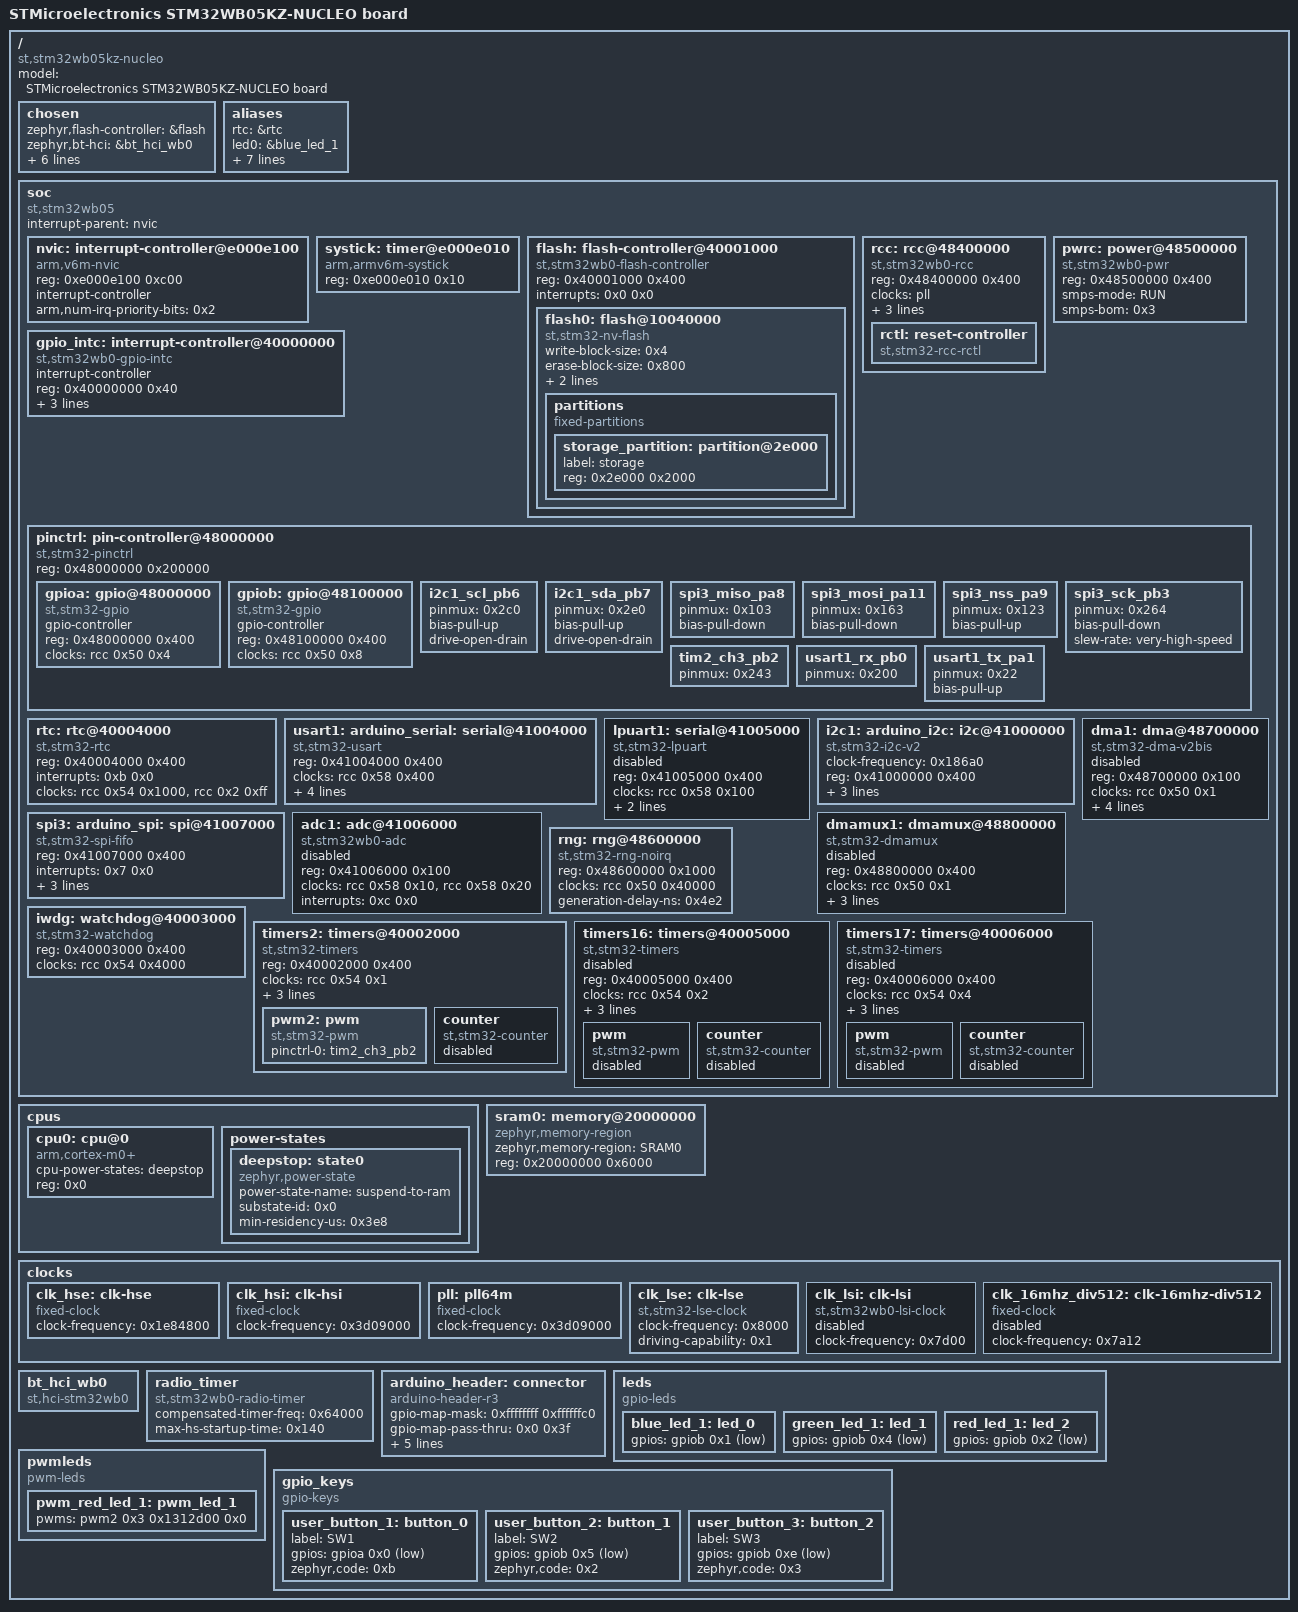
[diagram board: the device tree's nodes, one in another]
/dts-v1/;

/* node '/' defined in zephyr/dts/common/skeleton.dtsi:9 */
/ {
	model = "STMicroelectronics STM32WB05KZ-NUCLEO board"; /* in zephyr/boards/st/nucleo_wb05kz/nucleo_wb05kz.dts:15 */
	compatible = "st,stm32wb05kz-nucleo";                  /* in zephyr/boards/st/nucleo_wb05kz/nucleo_wb05kz.dts:16 */
	#address-cells = < 0x1 >;                              /* in zephyr/boards/st/nucleo_wb05kz/nucleo_wb05kz.dts:18 */
	#size-cells = < 0x1 >;                                 /* in zephyr/boards/st/nucleo_wb05kz/nucleo_wb05kz.dts:19 */

	/* node '/chosen' defined in zephyr/dts/common/skeleton.dtsi:13 */
	chosen {
		zephyr,flash-controller = &flash; /* in zephyr/dts/arm/st/wb0/stm32wb0.dtsi:25 */
		zephyr,bt-hci = &bt_hci_wb0;      /* in zephyr/dts/arm/st/wb0/stm32wb0.dtsi:26 */
		zephyr,console = &usart1;         /* in zephyr/boards/st/nucleo_wb05kz/nucleo_wb05kz.dts:22 */
		zephyr,shell-uart = &usart1;      /* in zephyr/boards/st/nucleo_wb05kz/nucleo_wb05kz.dts:23 */
		zephyr,sram = &sram0;             /* in zephyr/boards/st/nucleo_wb05kz/nucleo_wb05kz.dts:24 */
		zephyr,flash = &flash0;           /* in zephyr/boards/st/nucleo_wb05kz/nucleo_wb05kz.dts:25 */
		zephyr,bt-c2h-uart = &usart1;     /* in zephyr/boards/st/nucleo_wb05kz/nucleo_wb05kz.dts:26 */
		zephyr,entropy = &rng;            /* in zephyr/boards/st/nucleo_wb05kz/nucleo_wb05kz.dts:27 */
	};

	/* node '/aliases' defined in zephyr/dts/common/skeleton.dtsi:15 */
	aliases {
		rtc = &rtc;                /* in zephyr/boards/st/nucleo_wb05kz/nucleo_wb05kz.dts:78 */
		led0 = &blue_led_1;        /* in zephyr/boards/st/nucleo_wb05kz/nucleo_wb05kz.dts:79 */
		led1 = &green_led_1;       /* in zephyr/boards/st/nucleo_wb05kz/nucleo_wb05kz.dts:80 */
		led2 = &red_led_1;         /* in zephyr/boards/st/nucleo_wb05kz/nucleo_wb05kz.dts:81 */
		pwm-led0 = &pwm_red_led_1; /* in zephyr/boards/st/nucleo_wb05kz/nucleo_wb05kz.dts:82 */
		sw0 = &user_button_1;      /* in zephyr/boards/st/nucleo_wb05kz/nucleo_wb05kz.dts:83 */
		sw1 = &user_button_2;      /* in zephyr/boards/st/nucleo_wb05kz/nucleo_wb05kz.dts:84 */
		sw2 = &user_button_3;      /* in zephyr/boards/st/nucleo_wb05kz/nucleo_wb05kz.dts:85 */
		watchdog0 = &iwdg;         /* in zephyr/boards/st/nucleo_wb05kz/nucleo_wb05kz.dts:86 */
	};

	/* node '/soc' defined in zephyr/dts/arm/armv6-m.dtsi:6 */
	soc {
		#address-cells = < 0x1 >;     /* in zephyr/dts/arm/armv6-m.dtsi:7 */
		#size-cells = < 0x1 >;        /* in zephyr/dts/arm/armv6-m.dtsi:8 */
		interrupt-parent = < &nvic >; /* in zephyr/dts/arm/armv6-m.dtsi:10 */
		ranges;                       /* in zephyr/dts/arm/armv6-m.dtsi:11 */
		compatible = "st,stm32wb05",
		             "st,stm32wb0",
		             "simple-bus";    /* in zephyr/dts/arm/st/wb0/stm32wb05.dtsi:11 */

		/* node '/soc/interrupt-controller@e000e100' defined in zephyr/dts/arm/armv6-m.dtsi:13 */
		nvic: interrupt-controller@e000e100 {
			#address-cells = < 0x1 >;            /* in zephyr/dts/arm/armv6-m.dtsi:14 */
			compatible = "arm,v6m-nvic";         /* in zephyr/dts/arm/armv6-m.dtsi:15 */
			reg = < 0xe000e100 0xc00 >;          /* in zephyr/dts/arm/armv6-m.dtsi:16 */
			interrupt-controller;                /* in zephyr/dts/arm/armv6-m.dtsi:17 */
			#interrupt-cells = < 0x2 >;          /* in zephyr/dts/arm/armv6-m.dtsi:18 */
			arm,num-irq-priority-bits = < 0x2 >; /* in zephyr/dts/arm/st/wb0/stm32wb0.dtsi:326 */
			phandle = < 0x1 >;                   /* in zephyr/dts/arm/armv6-m.dtsi:10 */
		};

		/* node '/soc/timer@e000e010' defined in zephyr/dts/arm/armv6-m.dtsi:21 */
		systick: timer@e000e010 {
			compatible = "arm,armv6m-systick"; /* in zephyr/dts/arm/armv6-m.dtsi:22 */
			reg = < 0xe000e010 0x10 >;         /* in zephyr/dts/arm/armv6-m.dtsi:23 */
		};

		/* node '/soc/flash-controller@40001000' defined in zephyr/dts/arm/st/wb0/stm32wb0.dtsi:125 */
		flash: flash-controller@40001000 {
			compatible = "st,stm32wb0-flash-controller",
			             "st,stm32-flash-controller";    /* in zephyr/dts/arm/st/wb0/stm32wb0.dtsi:126 */
			reg = < 0x40001000 0x400 >;                  /* in zephyr/dts/arm/st/wb0/stm32wb0.dtsi:127 */
			interrupts = < 0x0 0x0 >;                    /* in zephyr/dts/arm/st/wb0/stm32wb0.dtsi:128 */
			#address-cells = < 0x1 >;                    /* in zephyr/dts/arm/st/wb0/stm32wb0.dtsi:130 */
			#size-cells = < 0x1 >;                       /* in zephyr/dts/arm/st/wb0/stm32wb0.dtsi:131 */

			/* node '/soc/flash-controller@40001000/flash@10040000' defined in zephyr/dts/arm/st/wb0/stm32wb0.dtsi:133 */
			flash0: flash@10040000 {
				compatible = "st,stm32-nv-flash",
				             "soc-nv-flash";      /* in zephyr/dts/arm/st/wb0/stm32wb0.dtsi:134 */
				write-block-size = < 0x4 >;       /* in zephyr/dts/arm/st/wb0/stm32wb0.dtsi:135 */
				erase-block-size = < 0x800 >;     /* in zephyr/dts/arm/st/wb0/stm32wb0.dtsi:136 */
				max-erase-time = < 0x28 >;        /* in zephyr/dts/arm/st/wb0/stm32wb0.dtsi:138 */
				reg = < 0x10040000 0x30000 >;     /* in zephyr/dts/arm/st/wb0/stm32wb05Xz.dtsi:13 */

				/* node '/soc/flash-controller@40001000/flash@10040000/partitions' defined in zephyr/boards/st/nucleo_wb05kz/nucleo_wb05kz.dts:179 */
				partitions {
					compatible = "fixed-partitions"; /* in zephyr/boards/st/nucleo_wb05kz/nucleo_wb05kz.dts:180 */
					#address-cells = < 0x1 >;        /* in zephyr/boards/st/nucleo_wb05kz/nucleo_wb05kz.dts:181 */
					#size-cells = < 0x1 >;           /* in zephyr/boards/st/nucleo_wb05kz/nucleo_wb05kz.dts:182 */

					/* node '/soc/flash-controller@40001000/flash@10040000/partitions/partition@2e000' defined in zephyr/boards/st/nucleo_wb05kz/nucleo_wb05kz.dts:185 */
					storage_partition: partition@2e000 {
						label = "storage";        /* in zephyr/boards/st/nucleo_wb05kz/nucleo_wb05kz.dts:186 */
						reg = < 0x2e000 0x2000 >; /* in zephyr/boards/st/nucleo_wb05kz/nucleo_wb05kz.dts:187 */
					};
				};
			};
		};

		/* node '/soc/rcc@48400000' defined in zephyr/dts/arm/st/wb0/stm32wb0.dtsi:142 */
		rcc: rcc@48400000 {
			compatible = "st,stm32wb0-rcc";  /* in zephyr/dts/arm/st/wb0/stm32wb0.dtsi:143 */
			reg = < 0x48400000 0x400 >;      /* in zephyr/dts/arm/st/wb0/stm32wb0.dtsi:144 */
			#clock-cells = < 0x2 >;          /* in zephyr/dts/arm/st/wb0/stm32wb0.dtsi:145 */
			clocks = < &pll >;               /* in zephyr/boards/st/nucleo_wb05kz/nucleo_wb05kz.dts:112 */
			clock-frequency = < 0x3d09000 >; /* in zephyr/boards/st/nucleo_wb05kz/nucleo_wb05kz.dts:113 */
			clksys-prescaler = < 0x1 >;      /* in zephyr/boards/st/nucleo_wb05kz/nucleo_wb05kz.dts:114 */
			slow-clock = < &clk_lse >;       /* in zephyr/boards/st/nucleo_wb05kz/nucleo_wb05kz.dts:115 */
			phandle = < 0x4 >;               /* in zephyr/dts/arm/st/wb0/stm32wb0.dtsi:186 */

			/* node '/soc/rcc@48400000/reset-controller' defined in zephyr/dts/arm/st/wb0/stm32wb0.dtsi:147 */
			rctl: reset-controller {
				compatible = "st,stm32-rcc-rctl"; /* in zephyr/dts/arm/st/wb0/stm32wb0.dtsi:148 */
				#reset-cells = < 0x1 >;           /* in zephyr/dts/arm/st/wb0/stm32wb0.dtsi:149 */
				phandle = < 0x5 >;                /* in zephyr/dts/arm/st/wb0/stm32wb0.dtsi:211 */
			};
		};

		/* node '/soc/power@48500000' defined in zephyr/dts/arm/st/wb0/stm32wb0.dtsi:153 */
		pwrc: power@48500000 {
			compatible = "st,stm32wb0-pwr"; /* in zephyr/dts/arm/st/wb0/stm32wb0.dtsi:154 */
			reg = < 0x48500000 0x400 >;     /* in zephyr/dts/arm/st/wb0/stm32wb0.dtsi:155 */
			smps-mode = "RUN";              /* in zephyr/boards/st/nucleo_wb05kz/nucleo_wb05kz.dts:91 */
			smps-bom = < 0x3 >;             /* in zephyr/boards/st/nucleo_wb05kz/nucleo_wb05kz.dts:92 */
		};

		/* node '/soc/interrupt-controller@40000000' defined in zephyr/dts/arm/st/wb0/stm32wb0.dtsi:163 */
		gpio_intc: interrupt-controller@40000000 {
			compatible = "st,stm32wb0-gpio-intc"; /* in zephyr/dts/arm/st/wb0/stm32wb0.dtsi:164 */
			interrupt-controller;                 /* in zephyr/dts/arm/st/wb0/stm32wb0.dtsi:165 */
			#interrupt-cells = < 0x1 >;           /* in zephyr/dts/arm/st/wb0/stm32wb0.dtsi:166 */
			#address-cells = < 0x1 >;             /* in zephyr/dts/arm/st/wb0/stm32wb0.dtsi:167 */
			reg = < 0x40000000 0x40 >;            /* in zephyr/dts/arm/st/wb0/stm32wb0.dtsi:168 */
			num-lines = < 0x20 >;                 /* in zephyr/dts/arm/st/wb0/stm32wb0.dtsi:169 */
			interrupts = < 0xf 0x0 >,
			             < 0x10 0x0 >;            /* in zephyr/dts/arm/st/wb0/stm32wb0.dtsi:170 */
			interrupt-names = "gpioa",
			                  "gpiob";            /* in zephyr/dts/arm/st/wb0/stm32wb0.dtsi:171 */
			line-ranges = < 0x0 0x10 >,
			              < 0x10 0x10 >;          /* in zephyr/dts/arm/st/wb0/stm32wb0.dtsi:172 */
		};

		/* node '/soc/pin-controller@48000000' defined in zephyr/dts/arm/st/wb0/stm32wb0.dtsi:175 */
		pinctrl: pin-controller@48000000 {
			compatible = "st,stm32-pinctrl"; /* in zephyr/dts/arm/st/wb0/stm32wb0.dtsi:176 */
			#address-cells = < 0x1 >;        /* in zephyr/dts/arm/st/wb0/stm32wb0.dtsi:177 */
			#size-cells = < 0x1 >;           /* in zephyr/dts/arm/st/wb0/stm32wb0.dtsi:178 */
			reg = < 0x48000000 0x200000 >;   /* in zephyr/dts/arm/st/wb0/stm32wb0.dtsi:179 */

			/* node '/soc/pin-controller@48000000/gpio@48000000' defined in zephyr/dts/arm/st/wb0/stm32wb0.dtsi:181 */
			gpioa: gpio@48000000 {
				compatible = "st,stm32-gpio"; /* in zephyr/dts/arm/st/wb0/stm32wb0.dtsi:182 */
				gpio-controller;              /* in zephyr/dts/arm/st/wb0/stm32wb0.dtsi:183 */
				#gpio-cells = < 0x2 >;        /* in zephyr/dts/arm/st/wb0/stm32wb0.dtsi:184 */
				reg = < 0x48000000 0x400 >;   /* in zephyr/dts/arm/st/wb0/stm32wb0.dtsi:185 */
				clocks = < &rcc 0x50 0x4 >;   /* in zephyr/dts/arm/st/wb0/stm32wb0.dtsi:186 */
				phandle = < 0x11 >;           /* in zephyr/boards/st/nucleo_wb05kz/arduino_r3_connector.dtsi:20 */
			};

			/* node '/soc/pin-controller@48000000/gpio@48100000' defined in zephyr/dts/arm/st/wb0/stm32wb0.dtsi:189 */
			gpiob: gpio@48100000 {
				compatible = "st,stm32-gpio"; /* in zephyr/dts/arm/st/wb0/stm32wb0.dtsi:190 */
				gpio-controller;              /* in zephyr/dts/arm/st/wb0/stm32wb0.dtsi:191 */
				#gpio-cells = < 0x2 >;        /* in zephyr/dts/arm/st/wb0/stm32wb0.dtsi:192 */
				reg = < 0x48100000 0x400 >;   /* in zephyr/dts/arm/st/wb0/stm32wb0.dtsi:193 */
				clocks = < &rcc 0x50 0x8 >;   /* in zephyr/dts/arm/st/wb0/stm32wb0.dtsi:194 */
				phandle = < 0x10 >;           /* in zephyr/boards/st/nucleo_wb05kz/arduino_r3_connector.dtsi:20 */
			};

			/* node '/soc/pin-controller@48000000/i2c1_scl_pb6' defined in modules/hal/stm32/dts/st/wb0/stm32wb05kzvx-pinctrl.dtsi:137 */
			i2c1_scl_pb6: i2c1_scl_pb6 {
				pinmux = < 0x2c0 >; /* in modules/hal/stm32/dts/st/wb0/stm32wb05kzvx-pinctrl.dtsi:138 */
				bias-pull-up;       /* in modules/hal/stm32/dts/st/wb0/stm32wb05kzvx-pinctrl.dtsi:139 */
				drive-open-drain;   /* in modules/hal/stm32/dts/st/wb0/stm32wb05kzvx-pinctrl.dtsi:140 */
				phandle = < 0x8 >;  /* in zephyr/boards/st/nucleo_wb05kz/nucleo_wb05kz.dts:148 */
			};

			/* node '/soc/pin-controller@48000000/i2c1_sda_pb7' defined in modules/hal/stm32/dts/st/wb0/stm32wb05kzvx-pinctrl.dtsi:151 */
			i2c1_sda_pb7: i2c1_sda_pb7 {
				pinmux = < 0x2e0 >; /* in modules/hal/stm32/dts/st/wb0/stm32wb05kzvx-pinctrl.dtsi:152 */
				bias-pull-up;       /* in modules/hal/stm32/dts/st/wb0/stm32wb05kzvx-pinctrl.dtsi:153 */
				drive-open-drain;   /* in modules/hal/stm32/dts/st/wb0/stm32wb05kzvx-pinctrl.dtsi:154 */
				phandle = < 0x9 >;  /* in zephyr/boards/st/nucleo_wb05kz/nucleo_wb05kz.dts:148 */
			};

			/* node '/soc/pin-controller@48000000/spi3_miso_pa8' defined in modules/hal/stm32/dts/st/wb0/stm32wb05kzvx-pinctrl.dtsi:211 */
			spi3_miso_pa8: spi3_miso_pa8 {
				pinmux = < 0x103 >; /* in modules/hal/stm32/dts/st/wb0/stm32wb05kzvx-pinctrl.dtsi:212 */
				bias-pull-down;     /* in modules/hal/stm32/dts/st/wb0/stm32wb05kzvx-pinctrl.dtsi:213 */
				phandle = < 0xc >;  /* in zephyr/boards/st/nucleo_wb05kz/nucleo_wb05kz.dts:154 */
			};

			/* node '/soc/pin-controller@48000000/spi3_mosi_pa11' defined in modules/hal/stm32/dts/st/wb0/stm32wb05kzvx-pinctrl.dtsi:218 */
			spi3_mosi_pa11: spi3_mosi_pa11 {
				pinmux = < 0x163 >; /* in modules/hal/stm32/dts/st/wb0/stm32wb05kzvx-pinctrl.dtsi:219 */
				bias-pull-down;     /* in modules/hal/stm32/dts/st/wb0/stm32wb05kzvx-pinctrl.dtsi:220 */
				phandle = < 0xd >;  /* in zephyr/boards/st/nucleo_wb05kz/nucleo_wb05kz.dts:154 */
			};

			/* node '/soc/pin-controller@48000000/spi3_nss_pa9' defined in modules/hal/stm32/dts/st/wb0/stm32wb05kzvx-pinctrl.dtsi:225 */
			spi3_nss_pa9: spi3_nss_pa9 {
				pinmux = < 0x123 >; /* in modules/hal/stm32/dts/st/wb0/stm32wb05kzvx-pinctrl.dtsi:226 */
				bias-pull-up;       /* in modules/hal/stm32/dts/st/wb0/stm32wb05kzvx-pinctrl.dtsi:227 */
				phandle = < 0xa >;  /* in zephyr/boards/st/nucleo_wb05kz/nucleo_wb05kz.dts:154 */
			};

			/* node '/soc/pin-controller@48000000/spi3_sck_pb3' defined in modules/hal/stm32/dts/st/wb0/stm32wb05kzvx-pinctrl.dtsi:238 */
			spi3_sck_pb3: spi3_sck_pb3 {
				pinmux = < 0x264 >;            /* in modules/hal/stm32/dts/st/wb0/stm32wb05kzvx-pinctrl.dtsi:239 */
				bias-pull-down;                /* in modules/hal/stm32/dts/st/wb0/stm32wb05kzvx-pinctrl.dtsi:240 */
				slew-rate = "very-high-speed"; /* in modules/hal/stm32/dts/st/wb0/stm32wb05kzvx-pinctrl.dtsi:241 */
				phandle = < 0xb >;             /* in zephyr/boards/st/nucleo_wb05kz/nucleo_wb05kz.dts:154 */
			};

			/* node '/soc/pin-controller@48000000/tim2_ch3_pb2' defined in modules/hal/stm32/dts/st/wb0/stm32wb05kzvx-pinctrl.dtsi:270 */
			tim2_ch3_pb2: tim2_ch3_pb2 {
				pinmux = < 0x243 >; /* in modules/hal/stm32/dts/st/wb0/stm32wb05kzvx-pinctrl.dtsi:271 */
				phandle = < 0xe >;  /* in zephyr/boards/st/nucleo_wb05kz/nucleo_wb05kz.dts:168 */
			};

			/* node '/soc/pin-controller@48000000/usart1_rx_pb0' defined in modules/hal/stm32/dts/st/wb0/stm32wb05kzvx-pinctrl.dtsi:405 */
			usart1_rx_pb0: usart1_rx_pb0 {
				pinmux = < 0x200 >; /* in modules/hal/stm32/dts/st/wb0/stm32wb05kzvx-pinctrl.dtsi:406 */
				phandle = < 0x7 >;  /* in zephyr/boards/st/nucleo_wb05kz/nucleo_wb05kz.dts:141 */
			};

			/* node '/soc/pin-controller@48000000/usart1_tx_pa1' defined in modules/hal/stm32/dts/st/wb0/stm32wb05kzvx-pinctrl.dtsi:423 */
			usart1_tx_pa1: usart1_tx_pa1 {
				pinmux = < 0x22 >; /* in modules/hal/stm32/dts/st/wb0/stm32wb05kzvx-pinctrl.dtsi:424 */
				bias-pull-up;      /* in modules/hal/stm32/dts/st/wb0/stm32wb05kzvx-pinctrl.dtsi:425 */
				phandle = < 0x6 >; /* in zephyr/boards/st/nucleo_wb05kz/nucleo_wb05kz.dts:141 */
			};
		};

		/* node '/soc/rtc@40004000' defined in zephyr/dts/arm/st/wb0/stm32wb0.dtsi:198 */
		rtc: rtc@40004000 {
			compatible = "st,stm32-rtc";   /* in zephyr/dts/arm/st/wb0/stm32wb0.dtsi:199 */
			reg = < 0x40004000 0x400 >;    /* in zephyr/dts/arm/st/wb0/stm32wb0.dtsi:200 */
			interrupts = < 0xb 0x0 >;      /* in zephyr/dts/arm/st/wb0/stm32wb0.dtsi:201 */
			clocks = < &rcc 0x54 0x1000 >,
			         < &rcc 0x2 0xff >;    /* in zephyr/boards/st/nucleo_wb05kz/nucleo_wb05kz.dts:123 */
			status = "okay";               /* in zephyr/boards/st/nucleo_wb05kz/nucleo_wb05kz.dts:125 */
		};

		/* node '/soc/serial@41004000' defined in zephyr/dts/arm/st/wb0/stm32wb0.dtsi:206 */
		usart1: arduino_serial: serial@41004000 {
			compatible = "st,stm32-usart",
			             "st,stm32-uart";                  /* in zephyr/dts/arm/st/wb0/stm32wb0.dtsi:207 */
			reg = < 0x41004000 0x400 >;                    /* in zephyr/dts/arm/st/wb0/stm32wb0.dtsi:208 */
			clocks = < &rcc 0x58 0x400 >;                  /* in zephyr/dts/arm/st/wb0/stm32wb0.dtsi:210 */
			resets = < &rctl 0x70a >;                      /* in zephyr/dts/arm/st/wb0/stm32wb0.dtsi:211 */
			interrupts = < 0x8 0x0 >;                      /* in zephyr/dts/arm/st/wb0/stm32wb0.dtsi:212 */
			pinctrl-0 = < &usart1_tx_pa1 &usart1_rx_pb0 >; /* in zephyr/boards/st/nucleo_wb05kz/nucleo_wb05kz.dts:141 */
			pinctrl-names = "default";                     /* in zephyr/boards/st/nucleo_wb05kz/nucleo_wb05kz.dts:142 */
			current-speed = < 0x1c200 >;                   /* in zephyr/boards/st/nucleo_wb05kz/nucleo_wb05kz.dts:143 */
			status = "okay";                               /* in zephyr/boards/st/nucleo_wb05kz/nucleo_wb05kz.dts:144 */
		};

		/* node '/soc/serial@41005000' defined in zephyr/dts/arm/st/wb0/stm32wb0.dtsi:216 */
		lpuart1: serial@41005000 {
			compatible = "st,stm32-lpuart",
			             "st,stm32-uart";   /* in zephyr/dts/arm/st/wb0/stm32wb0.dtsi:217 */
			reg = < 0x41005000 0x400 >;     /* in zephyr/dts/arm/st/wb0/stm32wb0.dtsi:218 */
			clocks = < &rcc 0x58 0x100 >;   /* in zephyr/dts/arm/st/wb0/stm32wb0.dtsi:219 */
			resets = < &rctl 0x708 >;       /* in zephyr/dts/arm/st/wb0/stm32wb0.dtsi:220 */
			interrupts = < 0x9 0x0 >;       /* in zephyr/dts/arm/st/wb0/stm32wb0.dtsi:221 */
			status = "disabled";            /* in zephyr/dts/arm/st/wb0/stm32wb0.dtsi:222 */
		};

		/* node '/soc/i2c@41000000' defined in zephyr/dts/arm/st/wb0/stm32wb0.dtsi:225 */
		i2c1: arduino_i2c: i2c@41000000 {
			compatible = "st,stm32-i2c-v2";              /* in zephyr/dts/arm/st/wb0/stm32wb0.dtsi:226 */
			clock-frequency = < 0x186a0 >;               /* in zephyr/dts/arm/st/wb0/stm32wb0.dtsi:227 */
			#address-cells = < 0x1 >;                    /* in zephyr/dts/arm/st/wb0/stm32wb0.dtsi:228 */
			#size-cells = < 0x0 >;                       /* in zephyr/dts/arm/st/wb0/stm32wb0.dtsi:229 */
			reg = < 0x41000000 0x400 >;                  /* in zephyr/dts/arm/st/wb0/stm32wb0.dtsi:230 */
			clocks = < &rcc 0x58 0x200000 >;             /* in zephyr/dts/arm/st/wb0/stm32wb0.dtsi:231 */
			interrupts = < 0x3 0x0 >;                    /* in zephyr/dts/arm/st/wb0/stm32wb0.dtsi:232 */
			interrupt-names = "combined";                /* in zephyr/dts/arm/st/wb0/stm32wb0.dtsi:233 */
			pinctrl-0 = < &i2c1_scl_pb6 &i2c1_sda_pb7 >; /* in zephyr/boards/st/nucleo_wb05kz/nucleo_wb05kz.dts:148 */
			pinctrl-names = "default";                   /* in zephyr/boards/st/nucleo_wb05kz/nucleo_wb05kz.dts:149 */
			status = "okay";                             /* in zephyr/boards/st/nucleo_wb05kz/nucleo_wb05kz.dts:150 */
		};

		/* node '/soc/spi@41007000' defined in zephyr/dts/arm/st/wb0/stm32wb0.dtsi:237 */
		spi3: arduino_spi: spi@41007000 {
			compatible = "st,stm32-spi-fifo",
			             "st,stm32-spi";                                                /* in zephyr/dts/arm/st/wb0/stm32wb0.dtsi:238 */
			#address-cells = < 0x1 >;                                                   /* in zephyr/dts/arm/st/wb0/stm32wb0.dtsi:239 */
			#size-cells = < 0x0 >;                                                      /* in zephyr/dts/arm/st/wb0/stm32wb0.dtsi:240 */
			reg = < 0x41007000 0x400 >;                                                 /* in zephyr/dts/arm/st/wb0/stm32wb0.dtsi:241 */
			interrupts = < 0x7 0x0 >;                                                   /* in zephyr/dts/arm/st/wb0/stm32wb0.dtsi:243 */
			pinctrl-0 = < &spi3_nss_pa9 &spi3_sck_pb3 &spi3_miso_pa8 &spi3_mosi_pa11 >; /* in zephyr/boards/st/nucleo_wb05kz/nucleo_wb05kz.dts:154 */
			pinctrl-names = "default";                                                  /* in zephyr/boards/st/nucleo_wb05kz/nucleo_wb05kz.dts:155 */
			status = "okay";                                                            /* in zephyr/boards/st/nucleo_wb05kz/nucleo_wb05kz.dts:156 */
			clocks = < &rcc 0x58 0x4000 >,
			         < &rcc 0x1 0x3360008 >;                                            /* in zephyr/boards/st/nucleo_wb05kz/nucleo_wb05kz.dts:158 */
		};

		/* node '/soc/adc@41006000' defined in zephyr/dts/arm/st/wb0/stm32wb0.dtsi:247 */
		adc1: adc@41006000 {
			compatible = "st,stm32wb0-adc"; /* in zephyr/dts/arm/st/wb0/stm32wb0.dtsi:248 */
			reg = < 0x41006000 0x100 >;     /* in zephyr/dts/arm/st/wb0/stm32wb0.dtsi:249 */
			clocks = < &rcc 0x58 0x10 >,
			         < &rcc 0x58 0x20 >;    /* in zephyr/dts/arm/st/wb0/stm32wb0.dtsi:256 */
			interrupts = < 0xc 0x0 >;       /* in zephyr/dts/arm/st/wb0/stm32wb0.dtsi:258 */
			#io-channel-cells = < 0x1 >;    /* in zephyr/dts/arm/st/wb0/stm32wb0.dtsi:259 */
			status = "disabled";            /* in zephyr/dts/arm/st/wb0/stm32wb0.dtsi:260 */
		};

		/* node '/soc/dma@48700000' defined in zephyr/dts/arm/st/wb0/stm32wb0.dtsi:263 */
		dma1: dma@48700000 {
			compatible = "st,stm32-dma-v2bis";                                                        /* in zephyr/dts/arm/st/wb0/stm32wb0.dtsi:264 */
			#dma-cells = < 0x2 >;                                                                     /* in zephyr/dts/arm/st/wb0/stm32wb0.dtsi:265 */
			reg = < 0x48700000 0x100 >;                                                               /* in zephyr/dts/arm/st/wb0/stm32wb0.dtsi:266 */
			clocks = < &rcc 0x50 0x1 >;                                                               /* in zephyr/dts/arm/st/wb0/stm32wb0.dtsi:267 */
			interrupts = < 0x11 0x0 0x11 0x0 0x11 0x0 0x11 0x0 0x11 0x0 0x11 0x0 0x11 0x0 0x11 0x0 >; /* in zephyr/dts/arm/st/wb0/stm32wb0.dtsi:268 */
			dma-requests = < 0x8 >;                                                                   /* in zephyr/dts/arm/st/wb0/stm32wb0.dtsi:269 */
			dma-offset = < 0x0 >;                                                                     /* in zephyr/dts/arm/st/wb0/stm32wb0.dtsi:270 */
			status = "disabled";                                                                      /* in zephyr/dts/arm/st/wb0/stm32wb0.dtsi:271 */
		};

		/* node '/soc/dmamux@48800000' defined in zephyr/dts/arm/st/wb0/stm32wb0.dtsi:274 */
		dmamux1: dmamux@48800000 {
			compatible = "st,stm32-dmamux"; /* in zephyr/dts/arm/st/wb0/stm32wb0.dtsi:275 */
			reg = < 0x48800000 0x400 >;     /* in zephyr/dts/arm/st/wb0/stm32wb0.dtsi:276 */
			clocks = < &rcc 0x50 0x1 >;     /* in zephyr/dts/arm/st/wb0/stm32wb0.dtsi:280 */
			#dma-cells = < 0x3 >;           /* in zephyr/dts/arm/st/wb0/stm32wb0.dtsi:281 */
			dma-channels = < 0x8 >;         /* in zephyr/dts/arm/st/wb0/stm32wb0.dtsi:282 */
			dma-generators = < 0x1 >;       /* in zephyr/dts/arm/st/wb0/stm32wb0.dtsi:283 */
			dma-requests = < 0x19 >;        /* in zephyr/dts/arm/st/wb0/stm32wb0.dtsi:284 */
			status = "disabled";            /* in zephyr/dts/arm/st/wb0/stm32wb0.dtsi:285 */
		};

		/* node '/soc/rng@48600000' defined in zephyr/dts/arm/st/wb0/stm32wb0.dtsi:296 */
		rng: rng@48600000 {
			compatible = "st,stm32-rng-noirq"; /* in zephyr/dts/arm/st/wb0/stm32wb0.dtsi:297 */
			reg = < 0x48600000 0x1000 >;       /* in zephyr/dts/arm/st/wb0/stm32wb0.dtsi:298 */
			clocks = < &rcc 0x50 0x40000 >;    /* in zephyr/dts/arm/st/wb0/stm32wb0.dtsi:299 */
			generation-delay-ns = < 0x4e2 >;   /* in zephyr/dts/arm/st/wb0/stm32wb0.dtsi:300 */
			status = "okay";                   /* in zephyr/boards/st/nucleo_wb05kz/nucleo_wb05kz.dts:175 */
		};

		/* node '/soc/watchdog@40003000' defined in zephyr/dts/arm/st/wb0/stm32wb0.dtsi:304 */
		iwdg: watchdog@40003000 {
			compatible = "st,stm32-watchdog"; /* in zephyr/dts/arm/st/wb0/stm32wb0.dtsi:305 */
			reg = < 0x40003000 0x400 >;       /* in zephyr/dts/arm/st/wb0/stm32wb0.dtsi:306 */
			clocks = < &rcc 0x54 0x4000 >;    /* in zephyr/dts/arm/st/wb0/stm32wb0.dtsi:307 */
			status = "okay";                  /* in zephyr/boards/st/nucleo_wb05kz/nucleo_wb05kz.dts:129 */
		};

		/* node '/soc/timers@40002000' defined in zephyr/dts/arm/st/wb0/stm32wb05.dtsi:13 */
		timers2: timers@40002000 {
			compatible = "st,stm32-timers"; /* in zephyr/dts/arm/st/wb0/stm32wb05.dtsi:14 */
			reg = < 0x40002000 0x400 >;     /* in zephyr/dts/arm/st/wb0/stm32wb05.dtsi:15 */
			clocks = < &rcc 0x54 0x1 >;     /* in zephyr/dts/arm/st/wb0/stm32wb05.dtsi:16 */
			resets = < &rctl 0x680 >;       /* in zephyr/dts/arm/st/wb0/stm32wb05.dtsi:17 */
			interrupts = < 0xa 0x0 >;       /* in zephyr/dts/arm/st/wb0/stm32wb05.dtsi:18 */
			interrupt-names = "global";     /* in zephyr/dts/arm/st/wb0/stm32wb05.dtsi:19 */
			status = "okay";                /* in zephyr/boards/st/nucleo_wb05kz/nucleo_wb05kz.dts:163 */
			st,prescaler = < 0x2710 >;      /* in zephyr/boards/st/nucleo_wb05kz/nucleo_wb05kz.dts:164 */

			/* node '/soc/timers@40002000/pwm' defined in zephyr/dts/arm/st/wb0/stm32wb05.dtsi:23 */
			pwm2: pwm {
				compatible = "st,stm32-pwm";   /* in zephyr/dts/arm/st/wb0/stm32wb05.dtsi:24 */
				#pwm-cells = < 0x3 >;          /* in zephyr/dts/arm/st/wb0/stm32wb05.dtsi:26 */
				pinctrl-0 = < &tim2_ch3_pb2 >; /* in zephyr/boards/st/nucleo_wb05kz/nucleo_wb05kz.dts:168 */
				pinctrl-names = "default";     /* in zephyr/boards/st/nucleo_wb05kz/nucleo_wb05kz.dts:169 */
				status = "okay";               /* in zephyr/boards/st/nucleo_wb05kz/nucleo_wb05kz.dts:170 */
				phandle = < 0x12 >;            /* in zephyr/boards/st/nucleo_wb05kz/nucleo_wb05kz.dts:51 */
			};

			/* node '/soc/timers@40002000/counter' defined in zephyr/dts/arm/st/wb0/stm32wb05.dtsi:29 */
			counter {
				compatible = "st,stm32-counter"; /* in zephyr/dts/arm/st/wb0/stm32wb05.dtsi:30 */
				status = "disabled";             /* in zephyr/dts/arm/st/wb0/stm32wb05.dtsi:31 */
			};
		};

		/* node '/soc/timers@40005000' defined in zephyr/dts/arm/st/wb0/stm32wb05.dtsi:35 */
		timers16: timers@40005000 {
			compatible = "st,stm32-timers"; /* in zephyr/dts/arm/st/wb0/stm32wb05.dtsi:36 */
			reg = < 0x40005000 0x400 >;     /* in zephyr/dts/arm/st/wb0/stm32wb05.dtsi:37 */
			clocks = < &rcc 0x54 0x2 >;     /* in zephyr/dts/arm/st/wb0/stm32wb05.dtsi:38 */
			resets = < &rctl 0x681 >;       /* in zephyr/dts/arm/st/wb0/stm32wb05.dtsi:39 */
			interrupts = < 0x1a 0x0 >;      /* in zephyr/dts/arm/st/wb0/stm32wb05.dtsi:40 */
			interrupt-names = "global";     /* in zephyr/dts/arm/st/wb0/stm32wb05.dtsi:41 */
			st,prescaler = < 0x0 >;         /* in zephyr/dts/arm/st/wb0/stm32wb05.dtsi:42 */
			status = "disabled";            /* in zephyr/dts/arm/st/wb0/stm32wb05.dtsi:43 */

			/* node '/soc/timers@40005000/pwm' defined in zephyr/dts/arm/st/wb0/stm32wb05.dtsi:45 */
			pwm {
				compatible = "st,stm32-pwm"; /* in zephyr/dts/arm/st/wb0/stm32wb05.dtsi:46 */
				status = "disabled";         /* in zephyr/dts/arm/st/wb0/stm32wb05.dtsi:47 */
				#pwm-cells = < 0x3 >;        /* in zephyr/dts/arm/st/wb0/stm32wb05.dtsi:48 */
			};

			/* node '/soc/timers@40005000/counter' defined in zephyr/dts/arm/st/wb0/stm32wb05.dtsi:51 */
			counter {
				compatible = "st,stm32-counter"; /* in zephyr/dts/arm/st/wb0/stm32wb05.dtsi:52 */
				status = "disabled";             /* in zephyr/dts/arm/st/wb0/stm32wb05.dtsi:53 */
			};
		};

		/* node '/soc/timers@40006000' defined in zephyr/dts/arm/st/wb0/stm32wb05.dtsi:57 */
		timers17: timers@40006000 {
			compatible = "st,stm32-timers"; /* in zephyr/dts/arm/st/wb0/stm32wb05.dtsi:58 */
			reg = < 0x40006000 0x400 >;     /* in zephyr/dts/arm/st/wb0/stm32wb05.dtsi:59 */
			clocks = < &rcc 0x54 0x4 >;     /* in zephyr/dts/arm/st/wb0/stm32wb05.dtsi:60 */
			resets = < &rctl 0x682 >;       /* in zephyr/dts/arm/st/wb0/stm32wb05.dtsi:61 */
			interrupts = < 0x1b 0x0 >;      /* in zephyr/dts/arm/st/wb0/stm32wb05.dtsi:62 */
			interrupt-names = "global";     /* in zephyr/dts/arm/st/wb0/stm32wb05.dtsi:63 */
			st,prescaler = < 0x0 >;         /* in zephyr/dts/arm/st/wb0/stm32wb05.dtsi:64 */
			status = "disabled";            /* in zephyr/dts/arm/st/wb0/stm32wb05.dtsi:65 */

			/* node '/soc/timers@40006000/pwm' defined in zephyr/dts/arm/st/wb0/stm32wb05.dtsi:67 */
			pwm {
				compatible = "st,stm32-pwm"; /* in zephyr/dts/arm/st/wb0/stm32wb05.dtsi:68 */
				status = "disabled";         /* in zephyr/dts/arm/st/wb0/stm32wb05.dtsi:69 */
				#pwm-cells = < 0x3 >;        /* in zephyr/dts/arm/st/wb0/stm32wb05.dtsi:70 */
			};

			/* node '/soc/timers@40006000/counter' defined in zephyr/dts/arm/st/wb0/stm32wb05.dtsi:73 */
			counter {
				compatible = "st,stm32-counter"; /* in zephyr/dts/arm/st/wb0/stm32wb05.dtsi:74 */
				status = "disabled";             /* in zephyr/dts/arm/st/wb0/stm32wb05.dtsi:75 */
			};
		};
	};

	/* node '/cpus' defined in zephyr/dts/arm/st/wb0/stm32wb0.dtsi:29 */
	cpus {
		#address-cells = < 0x1 >; /* in zephyr/dts/arm/st/wb0/stm32wb0.dtsi:30 */
		#size-cells = < 0x0 >;    /* in zephyr/dts/arm/st/wb0/stm32wb0.dtsi:31 */

		/* node '/cpus/cpu@0' defined in zephyr/dts/arm/st/wb0/stm32wb0.dtsi:33 */
		cpu0: cpu@0 {
			device_type = "cpu";              /* in zephyr/dts/arm/st/wb0/stm32wb0.dtsi:34 */
			compatible = "arm,cortex-m0+";    /* in zephyr/dts/arm/st/wb0/stm32wb0.dtsi:35 */
			cpu-power-states = < &deepstop >; /* in zephyr/dts/arm/st/wb0/stm32wb0.dtsi:36 */
			reg = < 0x0 >;                    /* in zephyr/dts/arm/st/wb0/stm32wb0.dtsi:37 */
		};

		/* node '/cpus/power-states' defined in zephyr/dts/arm/st/wb0/stm32wb0.dtsi:40 */
		power-states {

			/* node '/cpus/power-states/state0' defined in zephyr/dts/arm/st/wb0/stm32wb0.dtsi:41 */
			deepstop: state0 {
				compatible = "zephyr,power-state";   /* in zephyr/dts/arm/st/wb0/stm32wb0.dtsi:42 */
				power-state-name = "suspend-to-ram"; /* in zephyr/dts/arm/st/wb0/stm32wb0.dtsi:43 */
				substate-id = < 0x0 >;               /* in zephyr/dts/arm/st/wb0/stm32wb0.dtsi:44 */
				min-residency-us = < 0x3e8 >;        /* in zephyr/dts/arm/st/wb0/stm32wb0.dtsi:47 */
				phandle = < 0xf >;                   /* in zephyr/dts/arm/st/wb0/stm32wb0.dtsi:36 */
			};
		};
	};

	/* node '/memory@20000000' defined in zephyr/dts/arm/st/wb0/stm32wb0.dtsi:56 */
	sram0: memory@20000000 {
		compatible = "zephyr,memory-region",
		             "mmio-sram";            /* in zephyr/dts/arm/st/wb0/stm32wb0.dtsi:57 */
		zephyr,memory-region = "SRAM0";      /* in zephyr/dts/arm/st/wb0/stm32wb0.dtsi:58 */
		reg = < 0x20000000 0x6000 >;         /* in zephyr/dts/arm/st/wb0/stm32wb05Xz.dtsi:19 */
	};

	/* node '/clocks' defined in zephyr/dts/arm/st/wb0/stm32wb0.dtsi:61 */
	clocks {

		/* node '/clocks/clk-hse' defined in zephyr/dts/arm/st/wb0/stm32wb0.dtsi:66 */
		clk_hse: clk-hse {
			#clock-cells = < 0x0 >;          /* in zephyr/dts/arm/st/wb0/stm32wb0.dtsi:67 */
			compatible = "fixed-clock";      /* in zephyr/dts/arm/st/wb0/stm32wb0.dtsi:68 */
			clock-frequency = < 0x1e84800 >; /* in zephyr/dts/arm/st/wb0/stm32wb0.dtsi:69 */
			status = "okay";                 /* in zephyr/boards/st/nucleo_wb05kz/nucleo_wb05kz.dts:100 */
		};

		/* node '/clocks/clk-hsi' defined in zephyr/dts/arm/st/wb0/stm32wb0.dtsi:73 */
		clk_hsi: clk-hsi {
			#clock-cells = < 0x0 >;          /* in zephyr/dts/arm/st/wb0/stm32wb0.dtsi:74 */
			compatible = "fixed-clock";      /* in zephyr/dts/arm/st/wb0/stm32wb0.dtsi:75 */
			clock-frequency = < 0x3d09000 >; /* in zephyr/dts/arm/st/wb0/stm32wb0.dtsi:76 */
			status = "okay";                 /* in zephyr/boards/st/nucleo_wb05kz/nucleo_wb05kz.dts:104 */
		};

		/* node '/clocks/pll64m' defined in zephyr/dts/arm/st/wb0/stm32wb0.dtsi:83 */
		pll: pll64m {
			#clock-cells = < 0x0 >;          /* in zephyr/dts/arm/st/wb0/stm32wb0.dtsi:84 */
			compatible = "fixed-clock";      /* in zephyr/dts/arm/st/wb0/stm32wb0.dtsi:85 */
			clock-frequency = < 0x3d09000 >; /* in zephyr/dts/arm/st/wb0/stm32wb0.dtsi:86 */
			status = "okay";                 /* in zephyr/boards/st/nucleo_wb05kz/nucleo_wb05kz.dts:108 */
			phandle = < 0x2 >;               /* in zephyr/boards/st/nucleo_wb05kz/nucleo_wb05kz.dts:112 */
		};

		/* node '/clocks/clk-lse' defined in zephyr/dts/arm/st/wb0/stm32wb0.dtsi:94 */
		clk_lse: clk-lse {
			#clock-cells = < 0x0 >;            /* in zephyr/dts/arm/st/wb0/stm32wb0.dtsi:95 */
			compatible = "st,stm32-lse-clock"; /* in zephyr/dts/arm/st/wb0/stm32wb0.dtsi:96 */
			clock-frequency = < 0x8000 >;      /* in zephyr/dts/arm/st/wb0/stm32wb0.dtsi:97 */
			driving-capability = < 0x1 >;      /* in zephyr/dts/arm/st/wb0/stm32wb0.dtsi:98 */
			status = "okay";                   /* in zephyr/boards/st/nucleo_wb05kz/nucleo_wb05kz.dts:96 */
			phandle = < 0x3 >;                 /* in zephyr/boards/st/nucleo_wb05kz/nucleo_wb05kz.dts:115 */
		};

		/* node '/clocks/clk-lsi' defined in zephyr/dts/arm/st/wb0/stm32wb0.dtsi:102 */
		clk_lsi: clk-lsi {
			#clock-cells = < 0x0 >;               /* in zephyr/dts/arm/st/wb0/stm32wb0.dtsi:106 */
			compatible = "st,stm32wb0-lsi-clock",
			             "fixed-clock";           /* in zephyr/dts/arm/st/wb0/stm32wb0.dtsi:107 */
			clock-frequency = < 0x7d00 >;         /* in zephyr/dts/arm/st/wb0/stm32wb0.dtsi:108 */
			status = "disabled";                  /* in zephyr/dts/arm/st/wb0/stm32wb0.dtsi:109 */
		};

		/* node '/clocks/clk-16mhz-div512' defined in zephyr/dts/arm/st/wb0/stm32wb0.dtsi:116 */
		clk_16mhz_div512: clk-16mhz-div512 {
			#clock-cells = < 0x0 >;       /* in zephyr/dts/arm/st/wb0/stm32wb0.dtsi:117 */
			compatible = "fixed-clock";   /* in zephyr/dts/arm/st/wb0/stm32wb0.dtsi:118 */
			clock-frequency = < 0x7a12 >; /* in zephyr/dts/arm/st/wb0/stm32wb0.dtsi:119 */
			status = "disabled";          /* in zephyr/dts/arm/st/wb0/stm32wb0.dtsi:120 */
		};
	};

	/* node '/bt_hci_wb0' defined in zephyr/dts/arm/st/wb0/stm32wb0.dtsi:312 */
	bt_hci_wb0: bt_hci_wb0 {
		compatible = "st,hci-stm32wb0"; /* in zephyr/dts/arm/st/wb0/stm32wb0.dtsi:313 */
		status = "okay";                /* in zephyr/boards/st/nucleo_wb05kz/nucleo_wb05kz.dts:133 */
	};

	/* node '/radio_timer' defined in zephyr/dts/arm/st/wb0/stm32wb0.dtsi:317 */
	radio_timer: radio_timer {
		compatible = "st,stm32wb0-radio-timer"; /* in zephyr/dts/arm/st/wb0/stm32wb0.dtsi:318 */
		compensated-timer-freq = < 0x64000 >;   /* in zephyr/dts/arm/st/wb0/stm32wb0.dtsi:319 */
		max-hs-startup-time = < 0x140 >;        /* in zephyr/dts/arm/st/wb0/stm32wb0.dtsi:320 */
		status = "okay";                        /* in zephyr/boards/st/nucleo_wb05kz/nucleo_wb05kz.dts:137 */
	};

	/* node '/connector' defined in zephyr/boards/st/nucleo_wb05kz/arduino_r3_connector.dtsi:10 */
	arduino_header: connector {
		compatible = "arduino-header-r3";          /* in zephyr/boards/st/nucleo_wb05kz/arduino_r3_connector.dtsi:11 */
		#gpio-cells = < 0x2 >;                     /* in zephyr/boards/st/nucleo_wb05kz/arduino_r3_connector.dtsi:12 */
		gpio-map-mask = < 0xffffffff 0xffffffc0 >; /* in zephyr/boards/st/nucleo_wb05kz/arduino_r3_connector.dtsi:13 */
		gpio-map-pass-thru = < 0x0 0x3f >;         /* in zephyr/boards/st/nucleo_wb05kz/arduino_r3_connector.dtsi:14 */
		gpio-map = < 0xe 0x0 &gpiob 0xf 0x0 >,
		           < 0x10 0x0 &gpioa 0x9 0x0 >,
		           < 0x11 0x0 &gpioa 0xb 0x0 >,
		           < 0x12 0x0 &gpioa 0x8 0x0 >,
		           < 0x13 0x0 &gpiob 0x3 0x0 >,
		           < 0x14 0x0 &gpiob 0x7 0x0 >,
		           < 0x15 0x0 &gpiob 0x6 0x0 >;    /* in zephyr/boards/st/nucleo_wb05kz/arduino_r3_connector.dtsi:20 */
	};

	/* node '/leds' defined in zephyr/boards/st/nucleo_wb05kz/nucleo_wb05kz.dts:30 */
	leds: leds {
		compatible = "gpio-leds"; /* in zephyr/boards/st/nucleo_wb05kz/nucleo_wb05kz.dts:31 */

		/* node '/leds/led_0' defined in zephyr/boards/st/nucleo_wb05kz/nucleo_wb05kz.dts:33 */
		blue_led_1: led_0 {
			gpios = < &gpiob 0x1 0x11 >; /* in zephyr/boards/st/nucleo_wb05kz/nucleo_wb05kz.dts:34 */
		};

		/* node '/leds/led_1' defined in zephyr/boards/st/nucleo_wb05kz/nucleo_wb05kz.dts:37 */
		green_led_1: led_1 {
			gpios = < &gpiob 0x4 0x11 >; /* in zephyr/boards/st/nucleo_wb05kz/nucleo_wb05kz.dts:38 */
		};

		/* node '/leds/led_2' defined in zephyr/boards/st/nucleo_wb05kz/nucleo_wb05kz.dts:41 */
		red_led_1: led_2 {
			gpios = < &gpiob 0x2 0x11 >; /* in zephyr/boards/st/nucleo_wb05kz/nucleo_wb05kz.dts:42 */
		};
	};

	/* node '/pwmleds' defined in zephyr/boards/st/nucleo_wb05kz/nucleo_wb05kz.dts:46 */
	pwmleds: pwmleds {
		compatible = "pwm-leds"; /* in zephyr/boards/st/nucleo_wb05kz/nucleo_wb05kz.dts:47 */
		status = "okay";         /* in zephyr/boards/st/nucleo_wb05kz/nucleo_wb05kz.dts:48 */

		/* node '/pwmleds/pwm_led_1' defined in zephyr/boards/st/nucleo_wb05kz/nucleo_wb05kz.dts:50 */
		pwm_red_led_1: pwm_led_1 {
			pwms = < &pwm2 0x3 0x1312d00 0x0 >; /* in zephyr/boards/st/nucleo_wb05kz/nucleo_wb05kz.dts:51 */
		};
	};

	/* node '/gpio_keys' defined in zephyr/boards/st/nucleo_wb05kz/nucleo_wb05kz.dts:55 */
	gpio_keys {
		compatible = "gpio-keys"; /* in zephyr/boards/st/nucleo_wb05kz/nucleo_wb05kz.dts:56 */

		/* node '/gpio_keys/button_0' defined in zephyr/boards/st/nucleo_wb05kz/nucleo_wb05kz.dts:58 */
		user_button_1: button_0 {
			label = "SW1";               /* in zephyr/boards/st/nucleo_wb05kz/nucleo_wb05kz.dts:59 */
			gpios = < &gpioa 0x0 0x11 >; /* in zephyr/boards/st/nucleo_wb05kz/nucleo_wb05kz.dts:60 */
			zephyr,code = < 0xb >;       /* in zephyr/boards/st/nucleo_wb05kz/nucleo_wb05kz.dts:61 */
		};

		/* node '/gpio_keys/button_1' defined in zephyr/boards/st/nucleo_wb05kz/nucleo_wb05kz.dts:64 */
		user_button_2: button_1 {
			label = "SW2";               /* in zephyr/boards/st/nucleo_wb05kz/nucleo_wb05kz.dts:65 */
			gpios = < &gpiob 0x5 0x11 >; /* in zephyr/boards/st/nucleo_wb05kz/nucleo_wb05kz.dts:66 */
			zephyr,code = < 0x2 >;       /* in zephyr/boards/st/nucleo_wb05kz/nucleo_wb05kz.dts:67 */
		};

		/* node '/gpio_keys/button_2' defined in zephyr/boards/st/nucleo_wb05kz/nucleo_wb05kz.dts:70 */
		user_button_3: button_2 {
			label = "SW3";               /* in zephyr/boards/st/nucleo_wb05kz/nucleo_wb05kz.dts:71 */
			gpios = < &gpiob 0xe 0x11 >; /* in zephyr/boards/st/nucleo_wb05kz/nucleo_wb05kz.dts:72 */
			zephyr,code = < 0x3 >;       /* in zephyr/boards/st/nucleo_wb05kz/nucleo_wb05kz.dts:73 */
		};
	};
};
